# Z20K14xM register map
Vendor: Zhixin Semiconductor; Series: Z20K14xM; File version: 0.1.0
CPU: CM4 r0p1, little endian, no MPU, FPU, 4 interrupt priority bits
Registers are 32-bit, read-write, reset 0x0 unless marked. A register's access mark holds for its fields unless they carry their own. Offsets are from the block's base; [hi:lo] are bit positions; {n}, {i} and the like mark numbered series.

## TRNG
Base 0x40034000
0x00 TRNG_VERSION reset 0xC040003
  [31:0] VERSION — Version number of the IP
0x04 CTR_DRBG_VERSION reset 0xF020001
  [31:0] VERSION — Version number of the IP
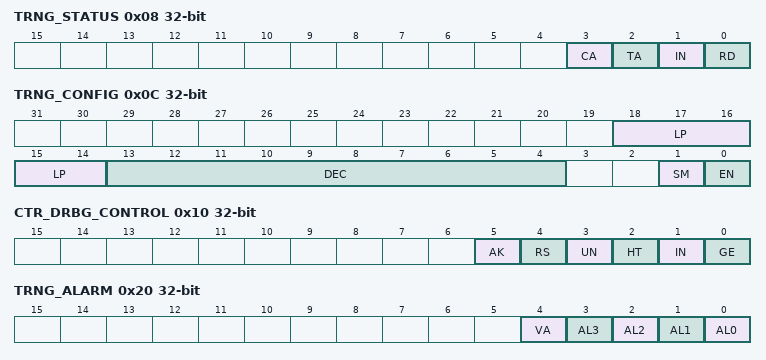
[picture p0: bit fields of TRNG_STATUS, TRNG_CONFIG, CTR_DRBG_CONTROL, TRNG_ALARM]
0x08 TRNG_STATUS
  [3] CA — CTR-DRBG Alarms Valid bit
  [2] TA — TRNG Alarms Valid bit
  [1] IN — CTR-DRBG instantiated bit.
  [0] RD — CTR-DRBG ready
0x0C TRNG_CONFIG
  [18:14] LP — Latency Parameter
  [13:4] DEC — Decimation parameter
  [1] SM — Stream mode enable bit
  [0] EN — CTR-DRBG enable bit
0x10 CTR_DRBG_CONTROL
  [5] AK — CTR-DRBG Alram acknowledgement bit
  [4] RS — CTR-DRBG release bit
  [3] UN — CTR-DRBG uninstantiate bit
  [2] HT — CTR-DRBG health test bit
  [1] IN — CTR-DTRB instantiate bit
  [0] GE — CTR-DRBG generate bit
0x14 CTR_DRBG_REQUEST_SIZE
  [11:0] RS — Number of 128-bit words that are requested.
0x18 CTR_DRBG_CONFIG_1 — CTR-DRBG Config register 1
  [31:0] RP — Number of generate requests between two reseeds.
0x1C CTR_DRBG_CONFIG_2 — CTR-DRBG Config register 2
  [31:0] HTP — Number of random generations between two periodic health tests.
0x20 TRNG_ALARM
  [4] VA — TRNG Alarm valid bit
  [3] AL3 — TRNG Alarm bit 3(Long run test)
  [2] AL2 — TRNG Alarm bit 2(run test)
  [1] AL1 — TRNG Alarm bit 1(poker test)
  [0] AL0 — TRNG Alarm bit 0(Monobit test)
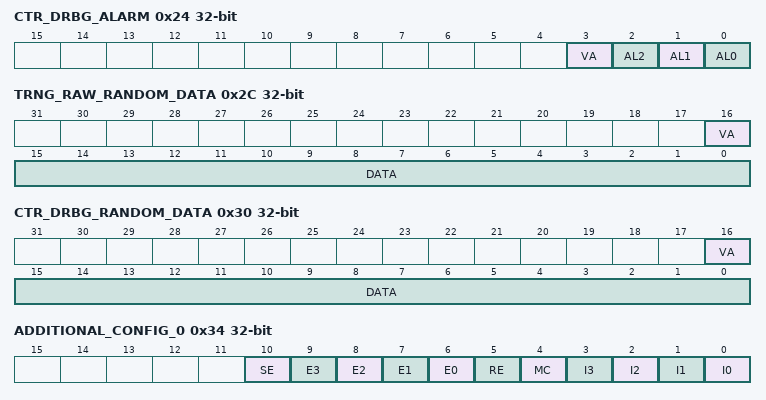
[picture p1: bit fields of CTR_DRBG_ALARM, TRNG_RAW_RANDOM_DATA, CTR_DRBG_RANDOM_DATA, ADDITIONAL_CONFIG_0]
0x24 CTR_DRBG_ALARM
  [3] VA — CTR-DRBG Alarm valid bit
  [2] AL2 — CTR-DRBG Alarm bit 2
  [1] AL1 — CTR-DRBG Alarm bit 1
  [0] AL0 — CTR-DRBG Alarm bit 0
0x28 TRNG_RAW_RANDOM_CONTROL
  [0] FL — Raw data fifo flush bit
0x2C TRNG_RAW_RANDOM_DATA
  [16] VA — TRNG raw random data valid bit
  [15:0] DATA — Raw random data
0x30 CTR_DRBG_RANDOM_DATA
  [16] VA — CTR-DRBG random data valid bit
  [15:0] DATA — CTR-TRBG random data
0x34 ADDITIONAL_CONFIG_0 — Additional Config register 0
  [10] SE — Noise module enable bit(Manual control)
  [9] E3 — Long run test(TRNG embedded tests) enable bit
  [8] E2 — Run test(TRNG embedded tests) enable bit
  [7] E1 — Poker run test(TRNG embedded tests) enable bit
  [6] E0 — Monobit test(TRNG embedded tests) enable bit
  [5] RE — Raw data recording enable bit
  [4] MC — Manual control enable bit
  [3] I3 — Long run test(TRNG embedded tests) ignore bit
  [2] I2 — Run test(TRNG embedded tests) ignore bit
  [1] I1 — Poker run test(TRNG embedded tests) ignore bit
  [0] I0 — Monobit test(TRNG embedded tests) ignore bit
0x38 ADDITIONAL_CONFIG_1 — Additional Config register 1
  [10:0] AC1 — Additional configuration word 1
0x3C ADDITIONAL_CONFIG_2 — Additional Config register 2
  [31:0] AC2 — Additional configuration word 2
0x40 ADDITIONAL_MEAS_CONTROL — Additional Measurement Control register
  [0] NS — Noise measurement start signal
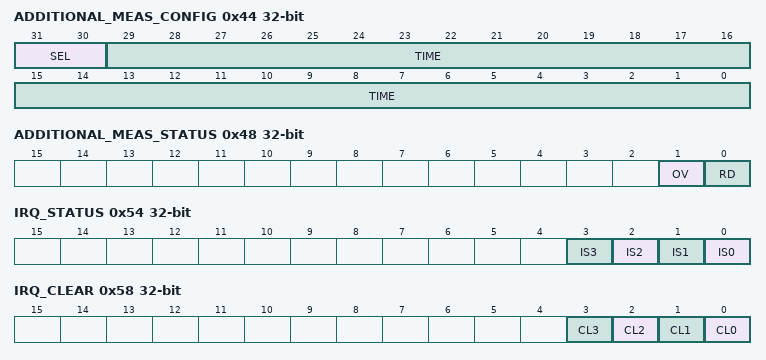
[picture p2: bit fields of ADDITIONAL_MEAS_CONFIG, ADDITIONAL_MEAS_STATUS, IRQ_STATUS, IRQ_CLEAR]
0x44 ADDITIONAL_MEAS_CONFIG — Additional Measurement Config register
  [31:30] SEL — Noise measurement selection
  [29:0] TIME — Noise measuremnt time
0x48 ADDITIONAL_MEAS_STATUS — Additional Measurement Status register
  [1] OV — Over
  [0] RD — Ready
0x4C ADDITIONAL_MEAS_DATA_0 — Additional Measurement Data register 0
  [31:0] D0 — noise measurement data 0
0x50 ADDITIONAL_MEAS_DATA_1 — Additional Measurement Data register 1
  [31:0] D1 — noise measurement data 1
0x54 IRQ_STATUS — Interrupt Request Status register
  [n] IS{n} (n=0..3) — IRQ status bit {n}
0x58 IRQ_CLEAR — Interrupt Request Clear register
  [n] CL{n} (n=0..3) — IRQ clear bit {n}
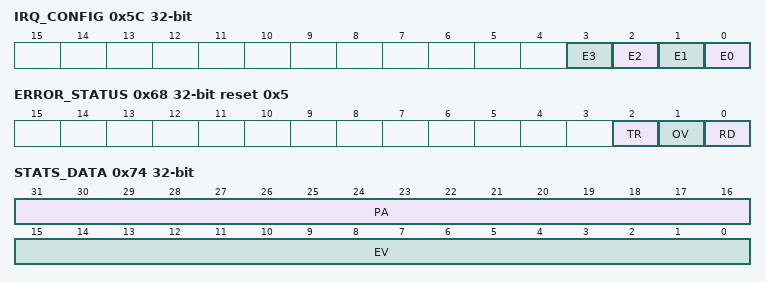
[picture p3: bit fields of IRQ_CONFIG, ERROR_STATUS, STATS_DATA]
0x5C IRQ_CONFIG — Interrupt Request Config register
  [n] E{n} (n=0..3) — IRQ Enable {n}
0x60 ERROR_CONFIG
  [31:0] TIMEOUT — Timeout value
0x64 ERROR_CONTROL
  [0] ST — Timeout start bit
0x68 ERROR_STATUS reset 0x5
  [2] TR — Timeout error
  [1] OV — Timeout module over
  [0] RD — Timeout module ready
0x6C STATS_CONFIG — TRNG Monitoring Feature Config register
  [0] MO — Monitoring feature enable
0x70 STATS_CONTROL — TRNG Monitoring Feature Control register
  [0] CL — Monitoring feature counter clear
0x74 STATS_DATA — TRNG Monitoring Feature status register
  [31:16] PA — Reserved
  [15:0] EV — Reserved
